# Polarfire SoC register map
Vendor: Microchip; File version: 1.0
CPU: Microchip PolarFire SoC 1.0, little endian
Registers are 32-bit, read-write, reset 0x0 unless marked. A register's access mark holds for its fields unless they carry their own. Offsets are from the block's base; [hi:lo] are bit positions; {n}, {i} and the like mark numbered series.

## GEM_A_LO (part 7 of 8) — GEM_A_LO Controller
Base 0x20110000
Same registers: GEM_B_LO 0x20112000, GEM_A_HI 0x28110000, GEM_B_HI 0x28112000
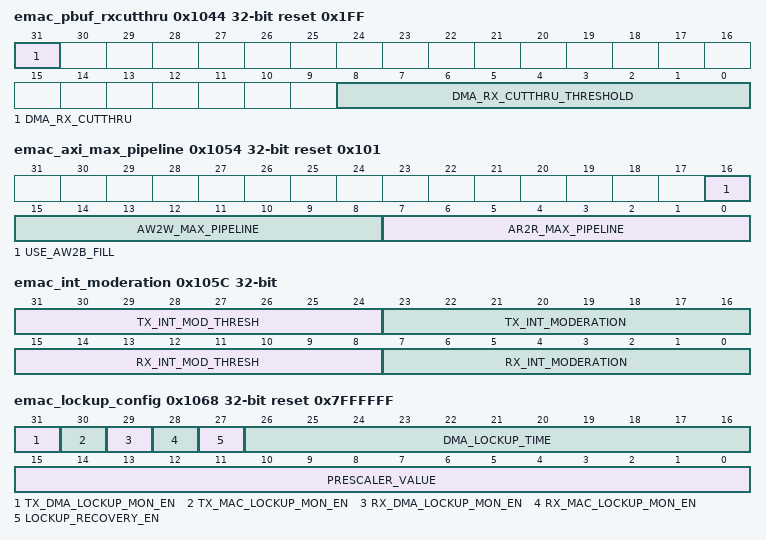
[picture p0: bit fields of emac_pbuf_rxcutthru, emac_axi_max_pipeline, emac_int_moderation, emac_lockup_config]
0x1044 emac_pbuf_rxcutthru reset 0x1FF — Receive Partial Store and Forward Register. Partial store and forward is only applicable when using the DMA configured in SRAM based packet buffer mode. It is also not available when using multi buffer frames. This register contains the enable bit and watermark value for receive cut-through operation.
  [31] DMA_RX_CUTTHRU — Enable RX partial store and forward operation
  [8:0] DMA_RX_CUTTHRU_THRESHOLD — Watermark value corresponding to number of SRAM locations. The actual number of bytes for the watermark is obtained by multiplying the watermark value by the value of the gem_rx_pbuf_data define divided by 8. The reset value depends on the value of the configuration option 'gem_emac_rx_pbuf_addr, which is defined in the verilog defs configuration file.
0x1048 emac_jumbo_max_length reset 0x2800 — Maximum Jumbo Frame Size.
  [13:0] JUMBO_MAX_LENGTH — Maximum Jumbo Frame Size - resets to the gem_jumbo_max_length define value.
0x1054 emac_axi_max_pipeline reset 0x101 — Used to set the maximum amount of outstanding transactions on the AXI bus between AR / R channels and AW / W channels. Cannot be more than the depth of the configured AXI pipeline FIFO (defined in verilog defs.v)
  [16] USE_AW2B_FILL — For the write issuing capability as defined in bits 15:8 of this register, select whether the max number of transactions operates between the AW to W AXI channel or the AW to B channel. Set to 0 to operate between the AW and W channels. Set to 1 to operate between the AW and B channels.
  [15:8] AW2W_MAX_PIPELINE — Defines the maximum number of outstanding AXI write requests that can be issued by the DMA via the AW channel. This is effectively the write issuing capability.
  [7:0] AR2R_MAX_PIPELINE — Defines the maximum number of outstanding AXI read requests that can be issued by the DMA via the AR channel. This is effectively the read issuing capability.
0x105C emac_int_moderation — Used to moderate the number of transmit and receive complete interrupts issued. With interrupt moderation enabled receive and transmit interrupts are not generated immediately a frame is transmitted or received. Instead when a receive or transmit event occurs a timer is started and the interrupt is asserted after it times out. This limits the frequency with which the CPU receives interrupts. When interrupt moderation is enabled interrupt status bit one is always used for receive and bit 7 is always used for transmit even when priority queuing is enabled. With interrupt moderation 800ns periods are counted. GEM determines what constitutes an 800ns period by looking at the tbi (bit 11), gigabit bit (10) and speed (bit 0) bits in the network configuration register and counting tx_clk cycles. Bit 0 needs to be set to 1 for 100M operation., :From release 1p11 onwards a frame threshold value may also be used to moderate interrupts. If both time based and frame threshold moderation is enabled the interrupt will be asserted as soon as the first moderation method expires.
  [31:24] TX_INT_MOD_THRESH — Count of transmitted frames before bit 7 is set in the interrupt status register. A non-zero value indicates transmit interrupt moderation will be performed.
  [23:16] TX_INT_MODERATION — Count of 800ns periods before bit 7 is set in the interrupt status register after a frame is transmitted. A non-zero value indicates transmit interrupt moderation will be performed.
  [15:8] RX_INT_MOD_THRESH — Count of received frames before bit 1 is set in the interrupt status register. A non-zero value indicates receive interrupt moderation will be performed.
  [7:0] RX_INT_MODERATION — Count of 800ns periods before bit 1 is set in the interrupt status register after a frame is received. A non-zero value indicates receive interrupt moderation will be performed.
0x1060 emac_sys_wake_time — Used to pause transmission after deassertion of tx_lpi_en. Each unit in this register corresponds to 25.6ns in 2.5G mode, 64ns in gigabit mode, 320ns in 100M mode and 3200ns at 10M. After tx_lpi_en is deasserted transmission will pause for the set time.
  [15:0] SYS_WAKE_TIME — Count of 25.6ns, 64ns, 320ns or 3200ns intervals before transmission starts after deassertion of tx_lpi_en (each interval is equivalent to eight tx_clk periods and so varies with data rate).
0x1068 emac_lockup_config reset 0x7FFFFFF — The lockup detection and recovery configuration register.
  [31] TX_DMA_LOCKUP_MON_EN — Enable the TX DMA lockup detector. Enable the monitor that detects lockups in the transmit DMA.
  [30] TX_MAC_LOCKUP_MON_EN — Enable the TX MAC lockup detector. Enable the monitor that detects lockups in the MAC transmit path.
  [29] RX_DMA_LOCKUP_MON_EN — Enable the RX DMA lockup detector. Enable the monitor that detects lockups in the receive DMA.
  [28] RX_MAC_LOCKUP_MON_EN — Enable the RX MAC lockup detector. Enable the monitor that detects lockups in the MAC receive path.
  [27] LOCKUP_RECOVERY_EN — Lockup recovery. If this bit is set then the module will go into a soft reset state if a lockup is detected on the transmit or receive data paths.
  [26:16] DMA_LOCKUP_TIME — Prior to release 1p11 this field was reserved. From release 1p11 onwards this field defines the timeout value for transmit and receive DMA lockup detection defined as a multiple of the prescaler value stored in bits 15:0 of this register.
  [15:0] PRESCALER_VALUE — For release 1p10 this field defined the time (measured in units of 1024 tx_clk periods) after which the lockup detection monitors would trigger, except for the receive MAC lock up detector which had its lockup time register. From release 1p11 onwards this field defines a prescaler value which is the number of tx_clk periods used to scale the timeout registers.
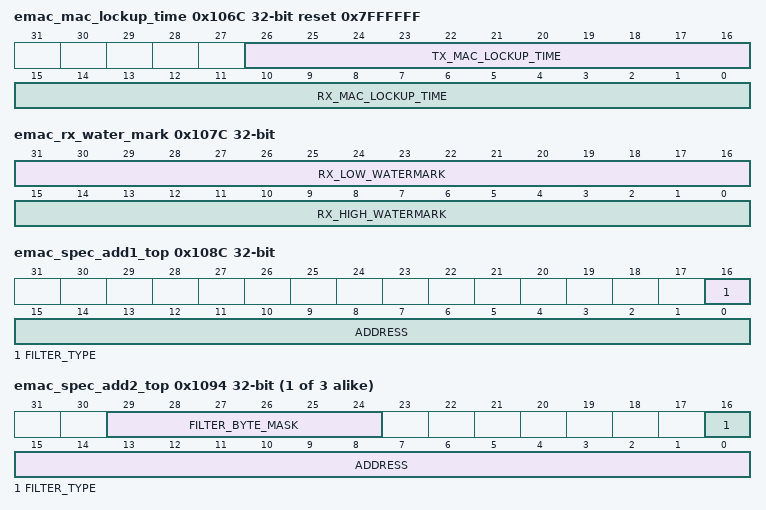
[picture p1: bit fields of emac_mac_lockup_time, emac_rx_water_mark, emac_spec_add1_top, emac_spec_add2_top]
0x106C emac_mac_lockup_time reset 0x7FFFFFF — MAC lockup detection time register. For receive this register specifies the maximum time between received frames. If no valid EOP is seen at the receive FIFO interface within the timer period then a lockup is considered to have occurred in the receive MAC. For transmit the MAC lockup time is simply the time it takes for data to be seen on the MII output pins after entering on the MAC FIFO interface.
  [26:16] TX_MAC_LOCKUP_TIME — Prior to release 1p11 this field was reserved. From release 1p11 onwards this field defines the timeout value for transmit MAC lockup detection defined as a multiple of the prescaler value stored in bits 15:0 of the lockup config register.
  [15:0] RX_MAC_LOCKUP_TIME — The time after which the receive MAC lockup detection monitor will trigger. For release 1p10 this was measured in units of 1024 tx_clk periods. From release 1p11 onwards it is used in conjunction with the prescaler stored in bits 15:0 of the lockup config register.
0x1070 emac_lockup_config3 — eMAC DMA TX Lockup Enable Control Register. This register enables the lockup timer for queue 0.
  [0] DMA_TX_LOCKUP_EN_Q_0 — Enable DMA TX lockup timer for queue 0.
0x107C emac_rx_water_mark — rx_water_mark - Receive water mark register. This register contains the high and low water-marks for automatic transmission of pause frames. The water-marks are compared against the internal signal rx_dpram_fill_lvl which is readable in the dpram_fill_dbg register; rx_dpram_fill_lvl indicates the number of words used in the receive SRAM (word length is configuration dependent and may be 4, 8 and 16 bytes). A value of zero in a field disables the corresponding functionality.
  [31:16] RX_LOW_WATERMARK — If this field is non-zero and the last pause frame transmitted was non-zero then a zero length pause frame is transmitted when the receive SRAM fill level falls below this value.
  [15:0] RX_HIGH_WATERMARK — If this field is non-zero and the receive SRAM fill level exceeds this value then a pause frame is transmitted
0x1080 emac_hash_bottom — The unicast hash enable and the multicast hash enable bits in the network configuration register enable the reception of hash matched frames. Hash Register Bottom 31:0.
  [31:0] ADDRESS — The first 32 bits of the hash address register.
0x1084 emac_hash_top — Hash Register Top 63:32
  [31:0] ADDRESS — The remaining 32 bits of the hash address register.
{0x1080+8i} emac_spec_add{i}_bottom (i=1..4) — The addresses stored in the specific address registers are deactivated at reset or when their corresponding specific address register bottom is written. They are activated when specific address register top is written.
  [31:0] ADDRESS — Octets 3 to 0 of the destination address, that is bits 31:0. Bit zero indicates whether the address is multicast or unicast and corresponds to the least significant bit of the first byte received. See the MAC Filtering Block of the user guide for more information on how to program this register.
0x108C emac_spec_add1_top — Specific Address Top
  [16] FILTER_TYPE — This control bit selects whether this filter should be comparing the MAC source address or the MAC destination address of the received Ethernet frame. When set to zero, the filter is a destination address filter. When set to one, the filter is a source address filter.
  [15:0] ADDRESS — Specific address 1. Octets 5 and 4 of the destination/source address that is to be compared, that is bits 47:32. See MAC Filtering Block of the user guide for more information.
{0x1084+8i} emac_spec_add{i}_top (i=2..4) — Specific Address Top
  [29:24] FILTER_BYTE_MASK — When high, the associated byte of the specific address will not be compared. Bit 24 controls whether the first byte received should be compared. Bit 29 controls whether the last byte received should be compared.
  [16] FILTER_TYPE — This control bit selects whether this filter should be comparing the MAC source address or the MAC destination address of the received Ethernet frame. When set to zero, the filter is a destination address filter. When set to one, the filter is a source address filter.
  [15:0] ADDRESS — Specific address 1. The most significant bits of the destination/source address that is to be compared, that is bits 47:32. See MAC Filtering Block of the user guide for more information.
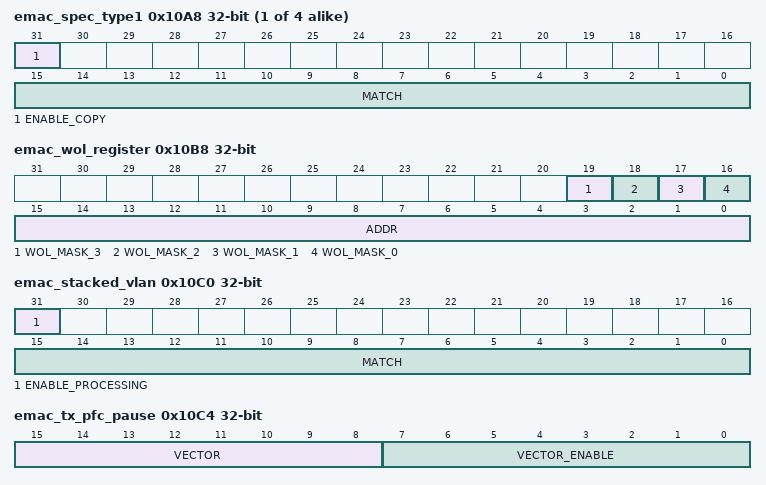
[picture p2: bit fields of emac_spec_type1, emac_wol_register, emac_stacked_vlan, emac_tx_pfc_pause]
{0x10A4+4i} emac_spec_type{i} (i=1..4) — Type ID Match {i}
  [31] ENABLE_COPY — Enable copying of type ID match {i} matched frames.
  [15:0] MATCH — Type ID match {i}. For use in comparisons with received frames type ID/length field.
0x10B8 emac_wol_register — Wake on LAN Register
  [19] WOL_MASK_3 — Wake on LAN multicast hash event enable. When set multicast hash events will cause the wol output to be asserted.
  [18] WOL_MASK_2 — Wake on LAN specific address register 1 event enable. When set specific address 1 events will cause the wol output to be asserted.
  [17] WOL_MASK_1 — Wake on LAN ARP request event enable. When set ARP request events will cause the wol output to be asserted.
  [16] WOL_MASK_0 — Wake on LAN magic packet event enable. When set magic packet events will cause the wol output to be asserted.
  [15:0] ADDR — Wake on LAN ARP request IP address. Written to define the least significant 16 bits of the target IP address that is matched to generate a Wake on LAN event. A value of zero will not generate an event, even if this is matched by the received frame.
0x10BC emac_stretch_ratio — IPG stretch register
  [15:0] IPG_STRETCH — IPG Stretch. Bits 7:0 are multiplied with the previously transmitted frame length (including preamble) bits 15:8 +1 divide the frame length. If the resulting number is greater than 96 and bit 28 is set in the network configuration register then the resulting number is used for the transmit inter-packet-gap. 1 is added to bits 15:8 to prevent a divide by zero.
0x10C0 emac_stacked_vlan — Stacked VLAN Register
  [31] ENABLE_PROCESSING — Enable stacked VLAN processing mode
  [15:0] MATCH — User defined VLAN_TYPE field. When Stacked VLAN is enabled, the first VLAN tag in a received frame will only be accepted if the VLAN type field is equal to this user defined VLAN_TYPE OR equal to the standard VLAN type (0x8100). Note that the second VLAN tag of a Stacked VLAN packet will only be matched correctly if its VLAN_TYPE field equals 0x8100.
0x10C4 emac_tx_pfc_pause — Transmit PFC Pause Register
  [15:8] VECTOR — Priority Vector Pause Size. If bit 17 of the network control register is written with a one then for each entry equal to zero in the Transmit PFC Pause Register[15:8], the PFC pause frame's pause quantum field associated with that entry will be taken from the transmit pause quantum register. For each entry equal to one in the Transmit PFC Pause Register [15:8], the pause quantum associated with that entry will be zero.
  [7:0] VECTOR_ENABLE — Priority Vector Enable. If bit 17 of the network control register is written with a one then the priority enable vector of the PFC priority based pause frame will be set equal to the value stored in this register [7:0].
0x10C8 emac_mask_add1_bottom — Specific Address Mask 1 Bottom 31:0
  [31:0] ADDRESS_MASK — Specific Address Mask. Setting a bit to one masks the corresponding bit in the specific address 1 register
0x10CC emac_mask_add1_top — Specific Address Mask 1 Top 47:32
  [15:0] ADDRESS_MASK — Specific Address Mask. Setting a bit to one masks the corresponding bit in the specific address 1 register
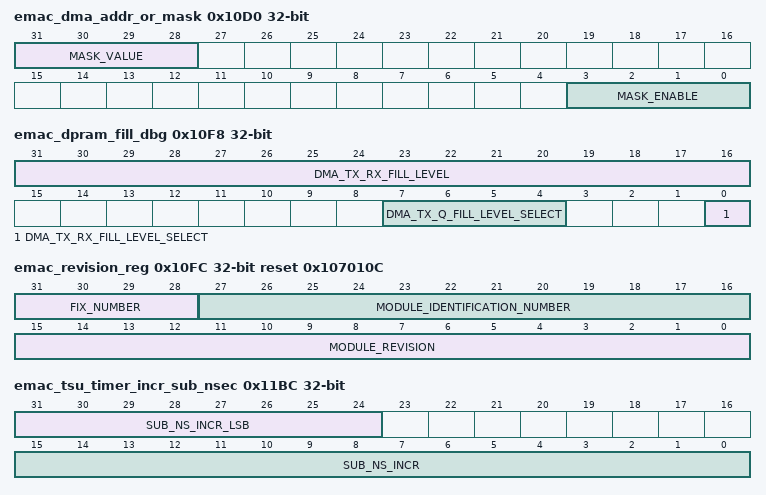
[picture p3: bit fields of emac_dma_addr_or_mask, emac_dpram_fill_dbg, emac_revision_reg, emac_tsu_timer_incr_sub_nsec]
0x10D0 emac_dma_addr_or_mask — Receive DMA Data Buffer Address Mask - only applies to AHB operation
  [31:28] MASK_VALUE — Data Buffer Address Mask Value. Values used to force bits 31:28 of the receive data buffer AHB address to a particular value when the associated enable bits stored in this register [3:0] are set. Any changes to this register will be ignored while the DMA is currently processing a receive packet. It will only affect the next full packet to be written to external system memory.
  [3:0] MASK_ENABLE — Data Buffer Address Mask Enable. These bits are associated directly with bits[31:28].When bit 0 is set, the AHB address bit 28 used for accessing the receive data buffers will be forced to the value stored in bit 28 of this register. When bit 1 is set, the AHB address bit 29 used for accessing the receive data buffers will be forced to the value stored in bit 29 of this register. When bit 2 is set, the AHB address bit 30 used for accessing the receive data buffers will be forced to the value stored in bit 30 of this register. When bit 3 is set, the AHB address bit 31 used for accessing the receive data buffers will be forced to the value stored in bit 31 of this register. When these bits are clear, the associated value stored in bits 31:28 have no effect on the AHB address used for receive data buffer accesses. Any changes to this register will be ignored while the DMA is currently processing a receive packet. It will only affect the next full packet to be written to external memory.
0x10D4 emac_rx_ptp_unicast — PTP RX unicast IP destination address
  [31:0] ADDRESS — Unicast IP destination address. Used for detection of PTP frames on receive path.
0x10D8 emac_tx_ptp_unicast — PTP TX unicast IP destination address
  [31:0] ADDRESS — Unicast IP destination address. Used for detection of PTP frames on transmit path.
0x10DC emac_tsu_nsec_cmp — TSU timer comparison value nanoseconds
  [21:0] COMPARISON_VALUE — TSU timer comparison value (ns). Value is compared to the bits[45:24] of the TSU timer count value (upper 22 bits of nanosecond value). The output tsu_timer_cmp_val is driven high when the timer comparison values match the TSU count value. From release 1p11 onwards this comparison only occurs once the nanosecond compare register has been written and when the match occurs tsu_timer_cmp_val will only be driven high for a single tsu_clk period.
0x10E0 emac_tsu_sec_cmp — TSU timer comparison value seconds 31:0
  [31:0] COMPARISON_VALUE — TSU timer comparison value (s). Value is compared to seconds value bits [31:0] of the TSU timer count value.
0x10E4 emac_tsu_msb_sec_cmp — TSU timer comparison value seconds 47:32
  [15:0] COMPARISON_VALUE — TSU timer comparison value (s). Value is compared to the top 16 bits (most significant 16-bits [47:32] of seconds value) of the TSU timer count value.
0x10E8 emac_tsu_ptp_tx_msb_sec ro — PTP Event Frame Transmitted Seconds Register 47:32
  [15:0] TIMER_SECONDS — PTP Event Frame TX Seconds. The register is updated with the value that the 1588 timer seconds register held when the SFD of a PTP transmit primary event crosses the MII interface. The actual update occurs when the GEM recognizes the frame as a PTP sync or delay_req frame. An interrupt is issued when the register is updated.
0x10EC emac_tsu_ptp_rx_msb_sec ro — PTP Event Frame Received Seconds Register 47:32
  [15:0] TIMER_SECONDS — PTP Event Frame TX Seconds. The register is updated with the value that the 1588 timer seconds register held when the SFD of a PTP receive primary event crosses the MII interface. The actual update occurs when the GEM recognizes the frame as a PTP sync or delay_req frame. An interrupt is issued when the register is updated.
0x10F0 emac_tsu_peer_tx_msb_sec ro — PTP Peer Event Frame Transmitted Seconds Register 47:32
  [15:0] TIMER_SECONDS — PTP Peer Event Frame TX Seconds. The register is updated with the value that the 1588 timer seconds register held when the SFD of a PTP transmit peer event crosses the MII interface. The actual update occurs when the GEM recognizes the frame as a PTP pdelay_req or pdelay_resp frame. An interrupt is issued when the register is updated.
0x10F4 emac_tsu_peer_rx_msb_sec ro — PTP Peer Event Frame Received Seconds Register 47:32
  [15:0] TIMER_SECONDS — PTP Peer Event Frame RX Seconds. The register is updated with the value that the 1588 timer seconds register held when the SFD of a PTP receive peer event crosses the MII interface. The actual update occurs when the GEM recognizes the frame as a PTP pdelay_req or pdelay_resp frame. An interrupt is issued when the register is updated.
0x10F8 emac_dpram_fill_dbg — The fill levels for the TX and RX packet buffer SRAMs can be read using this register, including the fill level for each queue in the TX direction. The fill level is reported as the number of word locations used. The number of bytes will depend on the SRAM data width.
  [31:16] DMA_TX_RX_FILL_LEVEL ro — Fill Level - TX or RX packet buffer fill level, selected by the tx_q_fill_level_select and tx_rx_fill_level_select registers. Read this register to determine the fill level.
  [7:4] DMA_TX_Q_FILL_LEVEL_SELECT — TX queue fill level select - select what TX queue to report fill levels for.
  [0] DMA_TX_RX_FILL_LEVEL_SELECT — TX/RX Fill Level select - report the fill level for the TX or RX packet buffer. Set 1 for transmit and 0 for receive.
0x10FC emac_revision_reg ro reset 0x107010C — This register indicates a Cadence module identification number and module revision. The value of this register is read only as defined by 'gem_revision_reg_value
  [31:28] FIX_NUMBER — Fix number - incremented for fix releases.
  [27:16] MODULE_IDENTIFICATION_NUMBER — Module identification number - for the GEM, this value is fixed.
  [15:0] MODULE_REVISION — Module revision - fixed value specific to the revision of the design which is incremented for each non-fix release of the IP.
0x1100 emac_octets_txed_bottom ro — These registers reset to zero on a read and stick at all ones when they count to their maximum value. They should be read frequently enough to prevent loss of data. In order to reduce overall design area, the statistics registers may be optionally removed in the configuration file if they are deemed unnecessary for a particular design. The receive statistics registers are only incremented when the receive enable bit is set in the network control register. The statistics registers optionally have a snapshot capability which, when exercised, will simultaneously store and clear the current values of all the statistics registers into a snapshot register set in order to allow a consistent set of statistics to be read by the processor. The snapshot is controlled using bit 13 of the network control register. The read snapshot control indicated by bit 14 of the network control register determines whether the processor reads the snapshot registers (logic 1) or the incrementing registers (logic 0). The default GEM configuration does not support the snapshot capability. See Parameterization section under Implementation Application Notes for an explanation of how to enable this function. All the statistics registers are read only. For test purposes they may be written by setting bit 7 (Write Enable) in the network control register. Setting bit 6 (increment statistics) in the network control register causes all the statistics registers to increment by one, again for test purposes. Once a statistics register has been read, it is automatically cleared. When reading the octets transmitted and octets received registers, bits 31:0 should be read prior to bits 47:32 to ensure reliable operation. The statistics register block contains the following registers. Octets Transmitted [31:0]
  [31:0] COUNT rw — Transmitted octets in frame without errors [31:0]. The number of octets transmitted in valid frames of any type. This counter is 48-bits, and is read through two registers. This count does not include octets from automatically generated pause frames.
0x1104 emac_octets_txed_top ro — Octets Transmitted 47:32
  [15:0] COUNT rw — Transmitted octets in frame without errors [47:32]. The number of octets transmitted in valid frames of any type. This counter is 48-bits, and is read through two registers. This count does not include octets from automatically generated pause frames.
0x1108 emac_frames_txed_ok ro — Frames Transmitted
  [31:0] COUNT rw — Frames transmitted without error. A 32 bit register counting the number of frames successfully transmitted, i.e. no under run and not too many retries. Excludes pause frames.
0x110C emac_broadcast_txed ro — Broadcast Frames Transmitted
  [31:0] COUNT rw — Broadcast frames transmitted without error. A 32 bit register counting the number of broadcast frames successfully transmitted without error, i.e. no under run and not too many retries. Excludes pause frames.
0x1110 emac_multicast_txed ro — Multicast Frames Transmitted
  [31:0] COUNT rw — Multicast frames transmitted without error. A 32 bit register counting the number of multicast frames successfully transmitted without error, i.e. no under run and not too many retries. Excludes pause frames.
0x1114 emac_pause_frames_txed ro — Pause Frames Transmitted
  [15:0] COUNT rw — Transmitted pause frames - a 16 bit register counting the number of pause frames transmitted. Only pause frames triggered by the register interface or through the external pause pins or automatically when rx_water_mark is reached are counted as pause frames. Pause frames received through the external FIFO interface are counted in the frames transmitted counter.
0x1118 emac_frames_txed_64 ro — 64 Byte Frames Transmitted
  [31:0] COUNT rw — 64 byte frames transmitted without error. A 32 bit register counting the number of 64 byte frames successfully transmitted without error, i.e. no under run and not too many retries. Excludes pause frames.
0x111C emac_frames_txed_65 ro — 65 to 127 Byte Frames Transmitted
  [31:0] COUNT rw — 65 to127 byte frames transmitted without error. A 32 bit register counting the number of 65 to127 byte frames successfully transmitted without error, i.e. no under run and not too many retries.
0x1120 emac_frames_txed_128 ro — 128 to 255 Byte Frames Transmitted
  [31:0] COUNT rw — 128 to 255 byte frames transmitted without error. A 32 bit register counting the number of 128 to 255 byte frames successfully transmitted without error, i.e. no under run and not too many retries.
0x1124 emac_frames_txed_256 ro — 256 to 511 Byte Frames Transmitted
  [31:0] COUNT rw — 256 to 511 byte frames transmitted without error. A 32 bit register counting the number of 256 to 511 byte frames successfully transmitted without error, i.e. no under run and not too many retries.
0x1128 emac_frames_txed_512 ro — 512 to 1023 Byte Frames Transmitted
  [31:0] COUNT rw — 512 to 1023 byte frames transmitted without error. A 32 bit register counting the number of 512 to 1023 byte frames successfully transmitted without error, i.e. no under run and not too many retries.
0x112C emac_frames_txed_1024 ro — 1024 to 1518 Byte Frames Transmitted
  [31:0] COUNT rw — 1024 to 1518 byte frames transmitted without error. A 32 bit register counting the number of 1024 to 1518 byte frames successfully transmitted without error, i.e. no under run and not too many retries.
0x1130 emac_frames_txed_1519 ro — Greater Than 1518 Byte Frames Transmitted
  [31:0] COUNT rw — Greater than 1518 byte frames transmitted without error. A 32 bit register counting the number of 1518 or above byte frames successfully transmitted without error, i.e. no under run and not too many retries.
0x1134 emac_tx_underruns ro — Transmit Under Runs
  [9:0] COUNT rw — Transmit under runs - a 10 bit register counting the number of frames not transmitted due to a transmit under run. If this register is incremented then no other statistics register is incremented.
0x1138 emac_single_collisions ro — Single Collision Frames
  [17:0] COUNT rw — Single collision frames - an 18 bit register counting the number of frames experiencing a single collision before being successfully transmitted, i.e. no under run.
0x113C emac_multiple_collisions ro — Multiple Collision Frames
  [17:0] COUNT rw — Multiple collision frames - an 18 bit register counting the number of frames experiencing between two and fifteen collisions prior to being successfully transmitted, i.e. no under run and not too many retries.
0x1140 emac_excessive_collisions ro — Excessive Collisions
  [9:0] COUNT rw — Excessive collisions - a 10 bit register counting the number of frames that failed to be transmitted because they experienced 16 collisions.
0x1144 emac_late_collisions ro — Late Collisions
  [9:0] COUNT rw — Late collisions - a 10 bit register counting the number of late collision occurring after the slot time (512 bits) has expired. In 10/100 mode, late collisions are counted twice i.e. both as a collision and a late collision. In gigabit mode, a late collision causes the transmission to be aborted, thus the single and multi collision registers are not updated.
0x1148 emac_deferred_frames ro — Deferred Transmission Frames
  [17:0] COUNT rw — Deferred transmission frames - an 18 bit register counting the number of frames experiencing deferral due to carrier sense being active on their first attempt at transmission. Frames involved in any collision are not counted nor are frames that experienced a transmit under run.
0x114C emac_crs_errors ro — Carrier Sense Errors
  [9:0] COUNT rw — Carrier sense errors - a 10 bit register counting the number of frames transmitted where carrier sense was not seen during transmission or where carrier sense was deasserted after being asserted in a transmit frame without collision (no under run). Only incremented in half-duplex mode. The only effect of a carrier sense error is to increment this register. The behaviour of the other statistics registers is unaffected by the detection of a carrier sense error.
0x1150 emac_octets_rxed_bottom ro — Octets Received 31:0
  [31:0] COUNT rw — Received octets in frame without errors [31:0]. The number of octets received in valid frames of any type. This counter is 48-bits and is read through two registers. This count does not include octets from pause frames, and is only incremented if the frame is successfully filtered.
0x1154 emac_octets_rxed_top ro — Octets Received 47:32
  [15:0] COUNT rw — Received octets in frame without errors [47:32]. The number of octets received in valid frames of any type. This counter is 48-bits and is read through two registers. This count does not include octets from pause frames, and is only incremented if the frame is successfully filtered.
0x1158 emac_frames_rxed_ok ro — Frames Received
  [31:0] COUNT rw — Frames received without error. A 32 bit register counting the number of frames successfully received. Excludes pause frames, and is only incremented if the frame is successfully filtered.
0x115C emac_broadcast_rxed ro — Broadcast Frames Received
  [31:0] COUNT rw — Broadcast frames received without error. A 32 bit register counting the number of broadcast frames successfully received without error. Excludes pause frames, and is only incremented if the frame is successfully filtered.
0x1160 emac_multicast_rxed ro — Multicast Frames Received
  [31:0] COUNT rw — Multicast frames received without error. A 32 bit register counting the number of multicast frames successfully received without error. Excludes pause frames, and is only incremented if the frame is successfully filtered.
0x1164 emac_pause_frames_rxed ro — Pause Frames Received
  [15:0] COUNT rw — Received pause frames - a 16 bit register counting the number of pause frames received without error.
0x1168 emac_frames_rxed_64 ro — 64 Byte Frames Received
  [31:0] COUNT rw — 64 byte frames received without error. A 32 bit register counting the number of 64 byte frames successfully received without error. Excludes pause frames, and is only incremented if the frame is successfully filtered.
0x116C emac_frames_rxed_65 ro — 65 to 127 Byte Frames Received
  [31:0] COUNT rw — 65 to 127 byte frames received without error. A 32 bit register counting the number of 65 to 127 byte frames successfully received without error. Excludes pause frames, and is only incremented if the frame is successfully filtered.
0x1170 emac_frames_rxed_128 ro — 128 to 255 Byte Frames Received
  [31:0] COUNT rw — 128 to 255 byte frames received without error. A 32 bit register counting the number of 128 to 255 byte frames successfully received without error. Excludes pause frames, and is only incremented if the frame is successfully filtered.
0x1174 emac_frames_rxed_256 ro — 256 to 511 Byte Frames Received
  [31:0] COUNT rw — 256 to 511 byte frames received without error. A 32 bit register counting the number of 256 to 511 byte frames successfully transmitted without error. Excludes pause frames, and is only incremented if the frame is successfully filtered.
0x1178 emac_frames_rxed_512 ro — 512 to 1023 Byte Frames Received
  [31:0] COUNT rw — 512 to 1023 byte frames received without error. A 32 bit register counting the number of 512 to 1023 byte frames successfully received without error. Excludes pause frames, and is only incremented if the frame is successfully filtered.
0x117C emac_frames_rxed_1024 ro — 1024 to 1518 Byte Frames Received
  [31:0] COUNT rw — 1024 to 1518 byte frames received without error. A 32 bit register counting the number of 1024 to 1518 byte frames successfully received without error. Excludes pause frames, and is only incremented if the frame is successfully filtered.
0x1180 emac_frames_rxed_1519 ro — 1519 to maximum Byte Frames Received
  [31:0] COUNT rw — 1519 to maximum byte frames received without error. A 32 bit register counting the number of 1519 byte or above frames successfully received without error. Maximum frame size is determined by the network configuration register bit 8 (1536 maximum frame size) or bit 3 (jumbo frame size). Excludes pause frames, and is only incremented if the frame is successfully filtered.
0x1184 emac_undersize_frames ro — Undersized Frames Received
  [9:0] COUNT rw — Undersize frames received - a 10 bit register counting the number of frames received less than 64 bytes in length (10/100 mode or gigabit mode, full duplex) that do not have either a CRC error or an alignment error. In gigabit mode, half-duplex, this register counts either frames not conforming to the minimum slot time of 512 bytes or frames not conforming to the minimum frame size once bursting is active.
0x1188 emac_excessive_rx_length ro — Oversize Frames Received
  [9:0] COUNT rw — Oversize frames received - a 10 bit register counting the number of frames received exceeding 1518 bytes (1536 bytes if bit 8 is set in network configuration register, 10,240 bytes if bit 3 is set in the network configuration register) in length but do not have either a CRC error, an alignment error nor a receive symbol error.
0x118C emac_rx_jabbers ro — Jabbers Received
  [9:0] COUNT rw — Jabbers received - a 10 bit register counting the number of frames received exceeding 1518 bytes (1536 if bit 8 set in network configuration register, 10,240 bytes if bit 3 is set in the network configuration register) in length and have either a CRC error, an alignment error or a receive symbol error.
0x1190 emac_fcs_errors ro — Frame Check Sequence Errors
  [9:0] COUNT rw — Frame check sequence errors - a 10 bit register counting frames that are an integral number of bytes, have bad CRC and are between 64 and 1518 bytes in length (1536 if bit 8 set in network configuration register, 10,240 bytes if bit 3 is set in the network configuration register). This register is also incremented if a symbol error is detected and the frame is of valid length and has an integral number of bytes. This register is incremented for a frame with bad FCS, regardless of whether it is copied to memory due to ignore FCS mode being enabled in bit 26 of the network configuration register.
0x1194 emac_rx_length_errors ro — Length Field Frame Errors
  [9:0] COUNT rw — Length field frame errors - this 10-bit register counts the number of frames received that have a measured length shorter than that extracted from the length field (bytes 13 and 14). This condition is only counted if the value of the length field is less than 0x0600, the frame is not of excessive length and checking is enabled through bit 16 of the network configuration register.
0x1198 emac_rx_symbol_errors ro — Receive Symbol Errors
  [9:0] COUNT rw — Receive symbol errors - a 10-bit register counting the number of frames that had rx_er asserted during reception. For 10/100 mode symbol errors are counted regardless of frame length checks. For gigabit mode the frame must satisfy slot time requirements in order to count a symbol error. Additionally, in gigabit half-duplex mode, carrier extension errors are also recorded. Receive symbol errors will also be counted as an FCS or alignment error if the frame is between 64 and 1518 bytes (1536 bytes if bit 8 is set in the network configuration register, 10240 bytes if bit 3 is set in the network configuration register). If the frame is larger it will be recorded as a jabber error.
0x119C emac_alignment_errors ro — Alignment Errors
  [9:0] COUNT rw — Alignment errors - a 10 bit register counting frames that are not an integral number of bytes long and have bad CRC when their length is truncated to an integral number of bytes and are between 64 and 1518 bytes in length (1536 if bit 8 set in network configuration register, 10,240 bytes if bit 3 is set in the network configuration register). This register is also incremented if a symbol error is detected and the frame is of valid length and does not have an integral number of bytes.
0x11A0 emac_rx_resource_errors ro — Receive Resource Errors
  [17:0] COUNT rw — Receive resource errors - an 18 bit register counting the number of times a receive buffer descriptor was read with its used bit set. This can be used as a means of checking the efficiency of the software in processing and releasing receive buffers. In an ideally configured system, this counter would not increase.
0x11A4 emac_rx_overruns ro — Receive Overruns
  [9:0] COUNT rw — Receive overruns - a 10 bit register counting the number of frames that are address recognized but were not copied to memory due to a receive overrun.
0x11A8 emac_rx_ip_ck_errors ro — IP Header Checksum Errors
  [7:0] COUNT rw — IP header checksum errors - an 8-bit register counting the number of frames discarded due to an incorrect IP header checksum, but are between 64 and 1518 bytes (1536 bytes if bit 8 is set in the network configuration register or 10240 bytes if bit 3 is in the network configuration register) and do not have a CRC error, an alignment error, nor a symbol error.
0x11AC emac_rx_tcp_ck_errors ro — TCP Checksum Errors
  [7:0] COUNT rw — TCP checksum errors - an 8-bit register counting the number of frames discarded due to an incorrect TCP checksum, but are between 64 and 1518 bytes (1536 bytes if bit 8 is set in the network configuration register or 10240 bytes if bit 3 is in the network configuration register) and do not have a CRC error, an alignment error, nor a symbol error.
0x11B0 emac_rx_udp_ck_errors ro — UDP Checksum Errors
  [7:0] COUNT rw — UDP checksum errors - an 8-bit register counting the number of frames discarded due to an incorrect UDP checksum, but are between 64 and 1518 bytes (1536 bytes if bit 8 is set in the network configuration register or 10240 bytes if bit 3 is in the network configuration register) and do not have a CRC error, an alignment error, nor a symbol error.
0x11B4 emac_auto_flushed_pkts ro — Receive DMA Flushed Packets
  [15:0] COUNT rw — Flushed RX packets counter. A 16 bit register counting the number of frames that have been flushed from the receive SRAM based packet buffer due to one of the following reasons:, :1. When either partial store and forward mode, bit 24 of the DMA configuration register, or the drop_on_resource_err mode of the traffic policing feature is active, and a packet is received while there is no AMBA (AHB/AXI) resource (no free descriptors for the DUT to use)., :2. When partial store and forward mode is enabled and an AMBA (AHB/AXI) error is encountered while writing the packet data to external memory., :3. When bit 18 of the network control register (software action to flush a packet from the head of the PBUF queue) is pulsed and the GEM DMA is not currently busy., :4. When a frame is dropped due to the policing actions defined in the rx_qX_flush registers located at 0x0b00-0x0b3c.
0x11BC emac_tsu_timer_incr_sub_nsec — 1588 Timer Increment Register sub nsec. From release 1p08f1 onwards this register must be written before the tsu_timer_incr register and the value written will not take effect until the tsu_timer_incr register is written to.
  [31:24] SUB_NS_INCR_LSB — These are the least significant bits [7:0] of the sub-ns value by which the 1588 timer will be incremented each clock cycle.
  [15:0] SUB_NS_INCR — These are the most significant bits [23:8] of the sub-ns value by which the 1588 timer will be incremented each clock cycle. 24 bits of sub nanosecond precision gives resolution of approximately 5.86E-17 seconds (16 bits gives 15.2 femtoseconds).
0x11C0 emac_tsu_timer_msb_sec — 1588 Timer Seconds Register 47:32
  [15:0] TIMER — TSU timer value (s). Most significant 16 bits of seconds timer count. The register is writeable. The 48-bit counter increments by one when the 1588 nanoseconds counter counts to one second. It may also be incremented or decremented when the timer adjust register is written (if decremented from zero the 48-bit combined count would roll back to 0xFFFFFFFFFFFF). Note: The value of this register is used only when the lower 32 bit register is written to. This is to ensure a single update of the 48 bit seconds value
0x11C4 emac_tsu_strobe_msb_sec ro — 1588 Timer Sync Strobe Seconds Register 47:32
  [15:0] STROBE — 1588 Timer Sync Strobe Seconds. The most significant 16-bit value of the Timer Seconds register captured when gem_tsu_ms and gem_tsu_inc_ctrl are zero.
0x11C8 emac_tsu_strobe_sec ro — 1588 Timer Sync Strobe Seconds Register 31:0
  [31:0] STROBE — 1588 Timer Sync Strobe Seconds. The lowest significant 32-bit value of the Timer Seconds register captured when gem_tsu_ms and gem_tsu_inc_ctrl are zero.
0x11CC emac_tsu_strobe_nsec ro — 1588 Timer Sync Strobe Nanoseconds Register
  [29:0] STROBE — 1588 Timer Sync Strobe Nanoseconds. The value of the Timer Nanoseconds register captured when gem_tsu_ms and gem_tsu_inc_ctrl are zero.
0x11D0 emac_tsu_timer_sec — 1588 Timer Seconds Register 31:0
  [31:0] TIMER — 1588 Timer Seconds Register. TSU timer value (s). Least significant 32 bits of seconds timer count. This register is writeable. The 48-bit counter increments by one when the 1588 nanoseconds counter counts to one second. It may also be incremented or decremented when the timer adjust register is written (if decremented from zero the 48-bit combined count would roll back to 0xFFFFFFFFFFFF).
0x11D4 emac_tsu_timer_nsec — 1588 Timer Nanoseconds Register
  [29:0] TIMER — Timer count in nanoseconds. This register is writeable. It can also be adjusted by writes to the 1588 timer adjust register. It increments by the value of the 1588 timer increment register each clock cycle (if this register is close to zero and a write to the timer adjust register causes a decrement the seconds register will be decremented if necessary and the nanoseconds register will roll back to 9999999xx (decimal)).
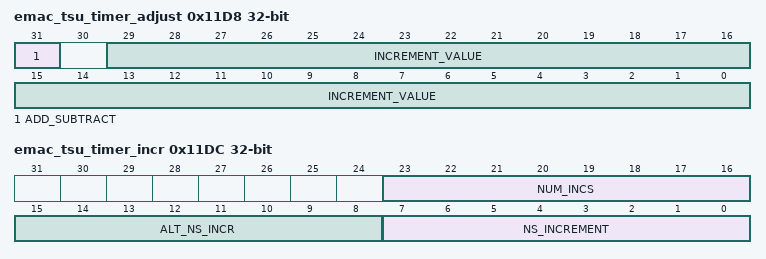
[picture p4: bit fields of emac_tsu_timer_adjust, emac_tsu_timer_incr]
0x11D8 emac_tsu_timer_adjust — This register is used to adjust the value of the timer in the TSU. It allows an integral number of nanoseconds to be added or subtracted from the timer in a one-off operation. This register returns all zeroes when read.
  [31] ADD_SUBTRACT — Write as one to subtract from the 1588 timer. Write as zero to add to it.
  [29:0] INCREMENT_VALUE — Timer increment value. The number of nanoseconds to increment or decrement the 1588 timer nanoseconds register. If necessary the 1588 seconds register will be incremented or decremented.
0x11DC emac_tsu_timer_incr — 1588 Timer Increment Register. From release 1p08f1 onwards this register must be written after the tsu_timer_incr_sub_ns register and the write operation will cause the value written to the tsu_timer_incr_sub_ns register to take effect.
  [23:16] NUM_INCS — Number of incs before alt inc. The number of increments after which the alternative increment is used.
  [15:8] ALT_NS_INCR — Alternative nanoseconds count. Alternative count of nanoseconds by which the 1588 timer nanoseconds register will be incremented each clock cycle.
  [7:0] NS_INCREMENT — A count of nanoseconds by which the 1588 timer nanoseconds register will be incremented each clock cycle. These are the most significant 8 bits of the 32 bit timer_increment counter. The tsu_timer_incr_sub_nsec register holds the least significant 24 bits of the increment.
0x11E0 emac_tsu_ptp_tx_sec ro — PTP Event Frame Transmitted Seconds Register 31:0
  [31:0] TIMER — PTP Event Frame Transmitted Seconds. The register is updated with the value that the 1588 timer seconds register held when the SFD of a PTP transmit primary event crosses the MII interface. The actual update occurs when the GEM recognizes the frame as a PTP sync or delay_req frame. An interrupt is issued when the register is updated.
0x11E4 emac_tsu_ptp_tx_nsec ro — PTP Event Frame Transmitted Nanoseconds Register
  [29:0] TIMER — PTP Event Frame Transmitted Nanoseconds. The register is updated with the value that the 1588 timer nanoseconds register held when the SFD of a PTP transmit primary event crosses the MII interface. The actual update occurs when the GEM recognizes the frame as a PTP sync or delay_req frame. An interrupt is issued when the register is updated.
0x11E8 emac_tsu_ptp_rx_sec ro — PTP Event Frame Received Seconds Register 31:0
  [31:0] TIMER — PTP Event Frame Received Seconds. The register is updated with the value that the 1588 timer seconds register held when the SFD of a PTP receive primary event crosses the MII interface. The actual update occurs when the GEM recognizes the frame as a PTP sync or delay_req frame. An interrupt is issued when the register is updated.
